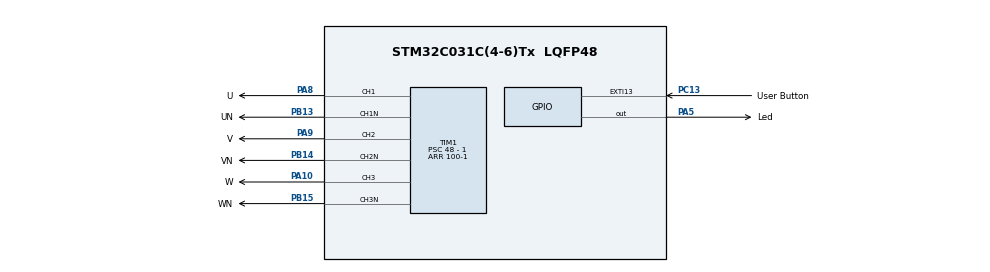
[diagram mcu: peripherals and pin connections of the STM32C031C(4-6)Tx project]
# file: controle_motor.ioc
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Mcu.Family=STM32C0
Mcu.Name=STM32C031C(4-6)Tx
Mcu.Package=LQFP48
NVIC.EXTI4_15_IRQn=true\:0\:0\:false\:false\:true\:true\:true\:true
NVIC.TIM3_IRQn=true\:0\:0\:false\:false\:true\:true\:true\:true
PA10.GPIO_Label=W
PA10.Signal=S_TIM1_CH3
PA13.GPIO_Label=DEBUG_SWDIO
PA13.Signal=DEBUG_SWDIO
PA14-BOOT0.GPIO_Label=DEBUG_SWCLK
PA14-BOOT0.Signal=DEBUG_SWCLK
PA2.GPIO_Label=VCP_USART2_TX
PA2.Signal=USART2_TX
PA3.GPIO_Label=VCP_USART2_RX
PA3.Signal=USART2_RX
PA5.GPIO_Label=Led
PA5.GPIO_Speed=GPIO_SPEED_FREQ_VERY_HIGH
PA5.PinState=GPIO_PIN_SET
PA5.Signal=GPIO_Output
PA8.GPIO_Label=U
PA8.Signal=S_TIM1_CH1
PA9.GPIO_Label=V
PA9.Signal=S_TIM1_CH2
PB13.GPIO_Label=UN
PB13.Mode=PWM Generation1 CH1 CH1N
PB13.Signal=TIM1_CH1N
PB14.GPIO_Label=VN
PB14.Mode=PWM Generation2 CH2 CH2N
PB14.Signal=TIM1_CH2N
PB15.GPIO_Label=WN
PB15.Mode=PWM Generation3 CH3 CH3N
PB15.Signal=TIM1_CH3N
PC13.GPIO_Label=User Button
PC13.Signal=GPXTI13
PC14-OSCX_IN\ (PC14).GPIO_Label=RCC_OSCX_IN
PC14-OSCX_IN\ (PC14).Mode=LSE-External-Oscillator
PC14-OSCX_IN\ (PC14).Signal=RCC_OSCX_IN
PC15-OSCX_OUT\ (PC15).GPIO_Label=RCC_OSCX_OUT
PC15-OSCX_OUT\ (PC15).Mode=LSE-External-Oscillator
PC15-OSCX_OUT\ (PC15).Signal=RCC_OSCX_OUT
PF0-OSC_IN\ (PF0).GPIO_Label=RCC_OSC_IN
PF0-OSC_IN\ (PF0).Mode=HSE-External-Oscillator
PF0-OSC_IN\ (PF0).Signal=RCC_OSC_IN
PF1-OSC_OUT\ (PF1).GPIO_Label=RCC_OSC_OUT
PF1-OSC_OUT\ (PF1).Mode=HSE-External-Oscillator
PF1-OSC_OUT\ (PF1).Signal=RCC_OSC_OUT
ProjectManager.HeapSize=0x200
ProjectManager.StackSize=0x400
ProjectManager.TargetToolchain=STM32CubeIDE
RCC.ADCFreq_Value=48000000
RCC.AHBFreq_Value=48000000
RCC.CortexFreq_Value=48000000
RCC.EXTERNAL_CLOCK_VALUE=12288000
RCC.HCLKFreq_Value=48000000
RCC.HSE_VALUE=48000000
RCC.HSISYSCLKDivider=RCC_HSI_DIV1
RCC.HSI_VALUE=48000000
RCC.SYSCLKFreq_VALUE=48000000
SH.S_TIM1_CH1.0=TIM1_CH1,PWM Generation1 CH1 CH1N
SH.S_TIM1_CH2.0=TIM1_CH2,PWM Generation2 CH2 CH2N
SH.S_TIM1_CH3.0=TIM1_CH3,PWM Generation3 CH3 CH3N
TIM1.AutoReloadPreload=TIM_AUTORELOAD_PRELOAD_ENABLE
TIM1.Channel-PWM\ Generation1\ CH1\ CH1N=TIM_CHANNEL_1
TIM1.Channel-PWM\ Generation2\ CH2\ CH2N=TIM_CHANNEL_2
TIM1.Channel-PWM\ Generation3\ CH3\ CH3N=TIM_CHANNEL_3
TIM1.DeadTime=96
TIM1.Period=100-1
TIM1.Prescaler=48 - 1
TIM1.Pulse-PWM\ Generation1\ CH1\ CH1N=50
TIM1.Pulse-PWM\ Generation2\ CH2\ CH2N=50
TIM1.Pulse-PWM\ Generation3\ CH3\ CH3N=50
TIM3.AutoReloadPreload=TIM_AUTORELOAD_PRELOAD_ENABLE
TIM3.Period=100 - 1
TIM3.Prescaler=48 - 1
VP_TIM1_VS_ClockSourceINT.Mode=Internal
VP_TIM3_VS_ClockSourceINT.Mode=Internal
board=NUCLEO-C031C6

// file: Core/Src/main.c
/* USER CODE BEGIN Header */
/**
  ******************************************************************************
  * @file           : main.c
  * @brief          : Main program body
  ******************************************************************************
  * @attention
  *
  * Copyright (c) 2025 STMicroelectronics.
  * All rights reserved.
  *
  * This software is licensed under terms that can be found in the LICENSE file
  * in the root directory of this software component.
  * If no LICENSE file comes with this software, it is provided AS-IS.
  *
  ******************************************************************************
  */
/* USER CODE END Header */
#include "main.h"
#include "tim.h"
#include "gpio.h"

/* USER CODE BEGIN Includes */
#include "controle_motor.h"
/* USER CODE END Includes */

void SystemClock_Config(void);

int main(void)
{

  /* MCU Configuration--------------------------------------------------------*/

  /* Reset of all peripherals, Initializes the Flash interface and the Systick. */
  HAL_Init();

  /* Configure the system clock */
  SystemClock_Config();

  /* Initialize all configured peripherals */
  MX_GPIO_Init();
  MX_TIM1_Init();
  MX_TIM3_Init();
  /* USER CODE BEGIN 2 */

  motor_init(); // Configura as variáveis iniciais

  // Inicia os PWMs do Motor
  HAL_TIM_PWM_Start(&htim1, TIM_CHANNEL_1);
  HAL_TIMEx_PWMN_Start(&htim1, TIM_CHANNEL_1);
  HAL_TIM_PWM_Start(&htim1, TIM_CHANNEL_2);
  HAL_TIMEx_PWMN_Start(&htim1, TIM_CHANNEL_2);
  HAL_TIM_PWM_Start(&htim1, TIM_CHANNEL_3);
  HAL_TIMEx_PWMN_Start(&htim1, TIM_CHANNEL_3);

  /* USER CODE END 2 */

  /* Infinite loop */
  while (1)
  {

    /* USER CODE BEGIN 3 */
	  motor_task();
  }
  /* USER CODE END 3 */
}

void SystemClock_Config(void)
{
  RCC_OscInitTypeDef RCC_OscInitStruct = {0};
  RCC_ClkInitTypeDef RCC_ClkInitStruct = {0};

  __HAL_FLASH_SET_LATENCY(FLASH_LATENCY_1);

  /** Initializes the RCC Oscillators according to the specified parameters
  * in the RCC_OscInitTypeDef structure.
  */
  RCC_OscInitStruct.OscillatorType = RCC_OSCILLATORTYPE_HSI;
  RCC_OscInitStruct.HSIState = RCC_HSI_ON;
  RCC_OscInitStruct.HSIDiv = RCC_HSI_DIV1;
  RCC_OscInitStruct.HSICalibrationValue = RCC_HSICALIBRATION_DEFAULT;
  if (HAL_RCC_OscConfig(&RCC_OscInitStruct) != HAL_OK)
  {
    Error_Handler();
  }

  /** Initializes the CPU, AHB and APB buses clocks
  */
  RCC_ClkInitStruct.ClockType = RCC_CLOCKTYPE_HCLK|RCC_CLOCKTYPE_SYSCLK
                              |RCC_CLOCKTYPE_PCLK1;
  RCC_ClkInitStruct.SYSCLKSource = RCC_SYSCLKSOURCE_HSI;
  RCC_ClkInitStruct.SYSCLKDivider = RCC_SYSCLK_DIV1;
  RCC_ClkInitStruct.AHBCLKDivider = RCC_HCLK_DIV1;
  RCC_ClkInitStruct.APB1CLKDivider = RCC_APB1_DIV1;

  if (HAL_RCC_ClockConfig(&RCC_ClkInitStruct, FLASH_LATENCY_1) != HAL_OK)
  {
    Error_Handler();
  }
}

/* USER CODE BEGIN 4 */
void HAL_TIM_PeriodElapsedCallback(TIM_HandleTypeDef *htim)
{
  // Se for o TIM3 (sua amostragem), chama o SPWM
  if (htim->Instance == TIM3)
  {
    spwm();
    calcula_rampa();
  }
}
/* USER CODE END 4 */

void Error_Handler(void)
{
  __disable_irq();
  while (1)
  {
  }
}
